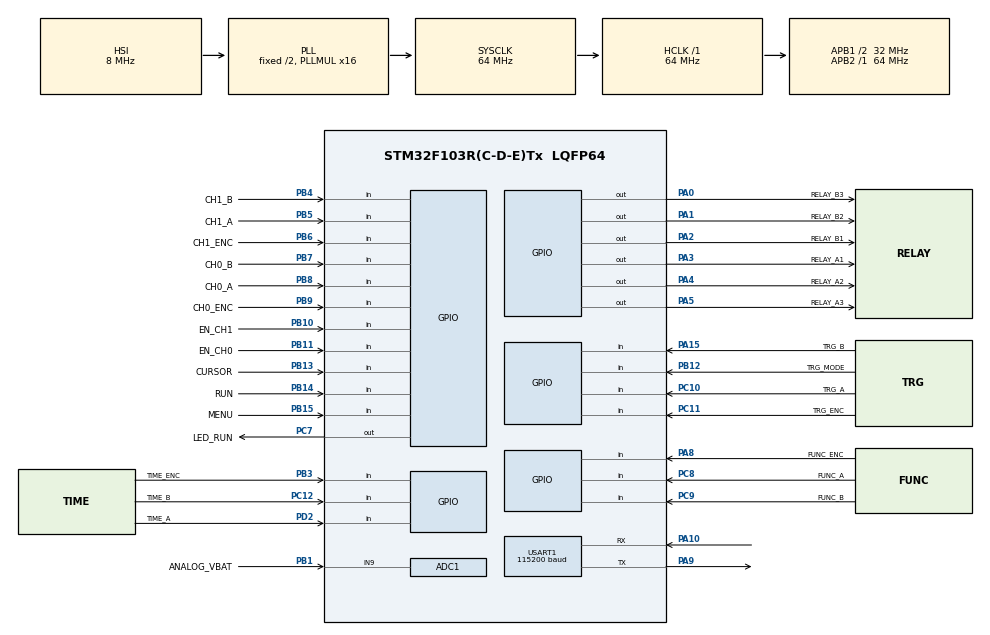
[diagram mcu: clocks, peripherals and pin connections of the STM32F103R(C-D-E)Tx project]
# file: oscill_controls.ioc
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ADC1.Channel-0\#ChannelRegularConversion=ADC_CHANNEL_9
ADC1.NbrOfConversionFlag=1
ADC1.Rank-0\#ChannelRegularConversion=1
ADC1.SamplingTime-0\#ChannelRegularConversion=ADC_SAMPLETIME_239CYCLES_5
ADC1.master=1
Mcu.Family=STM32F1
Mcu.Name=STM32F103R(C-D-E)Tx
Mcu.Package=LQFP64
NVIC.PriorityGroup=NVIC_PRIORITYGROUP_4
NVIC.USART1_IRQn=true\:2\:0\:false\:false\:true\:true\:true\:true
PA0-WKUP.GPIO_Label=RELAY_B3
PA0-WKUP.PinState=GPIO_PIN_SET
PA0-WKUP.Signal=GPIO_Output
PA1.GPIO_Label=RELAY_B2
PA1.PinState=GPIO_PIN_SET
PA1.Signal=GPIO_Output
PA10.Mode=Asynchronous
PA10.Signal=USART1_RX
PA13.Mode=Serial_Wire
PA13.Signal=SYS_JTMS-SWDIO
PA14.Mode=Serial_Wire
PA14.Signal=SYS_JTCK-SWCLK
PA15.GPIO_Label=TRG_B
PA15.GPIO_PuPd=GPIO_PULLUP
PA15.Signal=GPIO_Input
PA2.GPIO_Label=RELAY_B1
PA2.PinState=GPIO_PIN_RESET
PA2.Signal=GPIO_Output
PA3.GPIO_Label=RELAY_A1
PA3.PinState=GPIO_PIN_RESET
PA3.Signal=GPIO_Output
PA4.GPIO_Label=RELAY_A2
PA4.PinState=GPIO_PIN_SET
PA4.Signal=GPIO_Output
PA5.GPIO_Label=RELAY_A3
PA5.PinState=GPIO_PIN_SET
PA5.Signal=GPIO_Output
PA8.GPIO_Label=FUNC_ENC
PA8.GPIO_PuPd=GPIO_PULLUP
PA8.Signal=GPIO_Input
PA9.Mode=Asynchronous
PA9.Signal=USART1_TX
PB1.GPIO_Label=ANALOG_VBAT
PB1.Signal=ADCx_IN9
PB10.GPIO_Label=EN_CH1
PB10.GPIO_PuPd=GPIO_PULLUP
PB10.Signal=GPIO_Input
PB11.GPIO_Label=EN_CH0
PB11.GPIO_PuPd=GPIO_PULLUP
PB11.Signal=GPIO_Input
PB12.GPIO_Label=TRG_MODE
PB12.GPIO_PuPd=GPIO_PULLUP
PB12.Signal=GPIO_Input
PB13.GPIO_Label=CURSOR
PB13.GPIO_PuPd=GPIO_PULLUP
PB13.Signal=GPIO_Input
PB14.GPIO_Label=RUN
PB14.GPIO_PuPd=GPIO_PULLUP
PB14.Signal=GPIO_Input
PB15.GPIO_Label=MENU
PB15.GPIO_PuPd=GPIO_PULLUP
PB15.Signal=GPIO_Input
PB3.GPIO_Label=TIME_ENC
PB3.GPIO_PuPd=GPIO_PULLUP
PB3.Signal=GPIO_Input
PB4.GPIO_Label=CH1_B
PB4.GPIO_PuPd=GPIO_PULLUP
PB4.Signal=GPIO_Input
PB5.GPIO_Label=CH1_A
PB5.GPIO_PuPd=GPIO_PULLUP
PB5.Signal=GPIO_Input
PB6.GPIO_Label=CH1_ENC
PB6.GPIO_PuPd=GPIO_PULLUP
PB6.Signal=GPIO_Input
PB7.GPIO_Label=CH0_B
PB7.GPIO_PuPd=GPIO_PULLUP
PB7.Signal=GPIO_Input
PB8.GPIO_Label=CH0_A
PB8.GPIO_PuPd=GPIO_PULLUP
PB8.Signal=GPIO_Input
PB9.GPIO_Label=CH0_ENC
PB9.GPIO_PuPd=GPIO_PULLUP
PB9.Signal=GPIO_Input
PC10.GPIO_Label=TRG_A
PC10.GPIO_PuPd=GPIO_PULLUP
PC10.Signal=GPIO_Input
PC11.GPIO_Label=TRG_ENC
PC11.GPIO_PuPd=GPIO_PULLUP
PC11.Signal=GPIO_Input
PC12.GPIO_Label=TIME_B
PC12.GPIO_PuPd=GPIO_PULLUP
PC12.Signal=GPIO_Input
PC7.GPIO_Label=LED_RUN
PC7.PinState=GPIO_PIN_RESET
PC7.Signal=GPIO_Output
PC8.GPIO_Label=FUNC_A
PC8.GPIO_PuPd=GPIO_PULLUP
PC8.Signal=GPIO_Input
PC9.GPIO_Label=FUNC_B
PC9.GPIO_PuPd=GPIO_PULLUP
PC9.Signal=GPIO_Input
PD2.GPIO_Label=TIME_A
PD2.GPIO_PuPd=GPIO_PULLUP
PD2.Signal=GPIO_Input
ProjectManager.HeapSize=0x200
ProjectManager.StackSize=0x800
ProjectManager.TargetToolchain=MDK-ARM V5.32
RCC.ADCPresc=RCC_ADCPCLK2_DIV6
RCC.AHBFreq_Value=64000000
RCC.APB1CLKDivider=RCC_HCLK_DIV2
RCC.APB1Freq_Value=32000000
RCC.APB1TimFreq_Value=64000000
RCC.APB2Freq_Value=64000000
RCC.APB2TimFreq_Value=64000000
RCC.HCLKFreq_Value=64000000
RCC.PLLMUL=RCC_PLL_MUL16
RCC.PLLSourceVirtual=RCC_PLLSOURCE_HSI_DIV2
RCC.SYSCLKFreq_VALUE=64000000
RCC.SYSCLKSource=RCC_SYSCLKSOURCE_PLLCLK
RCC.USBFreq_Value=64000000
SH.ADCx_IN9.0=ADC1_IN9,IN9
USART1.BaudRate=115200
USART1.VirtualMode=VM_ASYNC
board=custom

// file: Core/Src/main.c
/* USER CODE BEGIN Header */
/**
  ******************************************************************************
  * @file           : main.c
  * @brief          : Main program body
  ******************************************************************************
  * @attention
  *
  * Copyright (c) 2026 STMicroelectronics.
  * All rights reserved.
  *
  * This software is licensed under terms that can be found in the LICENSE file
  * in the root directory of this software component.
  * If no LICENSE file comes with this software, it is provided AS-IS.
  *
  ******************************************************************************
  */
/* USER CODE END Header */
#include "main.h"
#include "adc.h"
#include "usart.h"
#include "gpio.h"

/* USER CODE BEGIN Includes */
#include "oscill_main.h"
/* USER CODE END Includes */

void SystemClock_Config(void);

int main(void)
{

  /* MCU Configuration--------------------------------------------------------*/

  /* Reset of all peripherals, Initializes the Flash interface and the Systick. */
  HAL_Init();

  /* Configure the system clock */
  SystemClock_Config();

  /* Initialize all configured peripherals */
  MX_GPIO_Init();
  MX_USART1_UART_Init();
  MX_ADC1_Init();
  /* USER CODE BEGIN 2 */
  /* Периферия готова: принять начальные уровни панели и назначить UART. */
  Oscill_Init();
  /* USER CODE END 2 */

  /* Infinite loop */
  while (1)
  {

    /* USER CODE BEGIN 3 */
    /* Опрос контактов и UART не ждут друг друга и не используют HAL_Delay. */
    Oscill_Process();
    /* Не усыплять ядро: ST-Link должен подключаться без линии NRST. */
  }
  /* USER CODE END 3 */
}

void SystemClock_Config(void)
{
  RCC_OscInitTypeDef RCC_OscInitStruct = {0};
  RCC_ClkInitTypeDef RCC_ClkInitStruct = {0};
  RCC_PeriphCLKInitTypeDef PeriphClkInit = {0};

  /** Initializes the RCC Oscillators according to the specified parameters
  * in the RCC_OscInitTypeDef structure.
  */
  RCC_OscInitStruct.OscillatorType = RCC_OSCILLATORTYPE_HSI;
  RCC_OscInitStruct.HSIState = RCC_HSI_ON;
  RCC_OscInitStruct.HSICalibrationValue = RCC_HSICALIBRATION_DEFAULT;
  RCC_OscInitStruct.PLL.PLLState = RCC_PLL_ON;
  RCC_OscInitStruct.PLL.PLLSource = RCC_PLLSOURCE_HSI_DIV2;
  RCC_OscInitStruct.PLL.PLLMUL = RCC_PLL_MUL16;
  if (HAL_RCC_OscConfig(&RCC_OscInitStruct) != HAL_OK)
  {
    Error_Handler();
  }

  /** Initializes the CPU, AHB and APB buses clocks
  */
  RCC_ClkInitStruct.ClockType = RCC_CLOCKTYPE_HCLK|RCC_CLOCKTYPE_SYSCLK
                              |RCC_CLOCKTYPE_PCLK1|RCC_CLOCKTYPE_PCLK2;
  RCC_ClkInitStruct.SYSCLKSource = RCC_SYSCLKSOURCE_PLLCLK;
  RCC_ClkInitStruct.AHBCLKDivider = RCC_SYSCLK_DIV1;
  RCC_ClkInitStruct.APB1CLKDivider = RCC_HCLK_DIV2;
  RCC_ClkInitStruct.APB2CLKDivider = RCC_HCLK_DIV1;

  if (HAL_RCC_ClockConfig(&RCC_ClkInitStruct, FLASH_LATENCY_2) != HAL_OK)
  {
    Error_Handler();
  }
  PeriphClkInit.PeriphClockSelection = RCC_PERIPHCLK_ADC;
  PeriphClkInit.AdcClockSelection = RCC_ADCPCLK2_DIV6;
  if (HAL_RCCEx_PeriphCLKConfig(&PeriphClkInit) != HAL_OK)
  {
    Error_Handler();
  }
}

void Error_Handler(void)
{
  __disable_irq();
  while (1)
  {
  }
}
